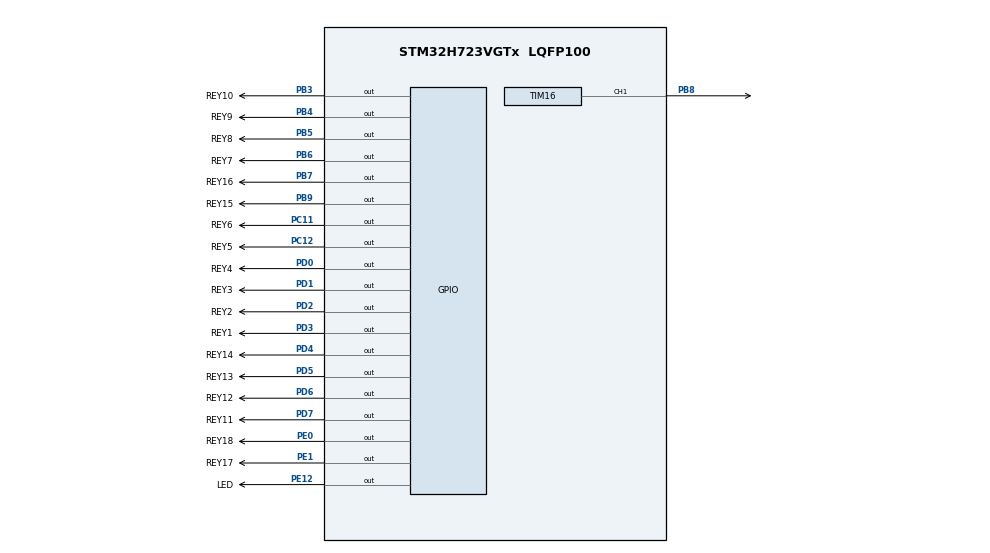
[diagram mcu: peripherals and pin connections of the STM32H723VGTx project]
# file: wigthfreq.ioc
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CORTEX_M7.default_mode_Activation=1
Mcu.Family=STM32H7
Mcu.Name=STM32H723VGTx
Mcu.Package=LQFP100
Mcu.UserConstants=PSC_VALUE,(1-1);ARR_VALUE,(12-1)
NVIC.PriorityGroup=NVIC_PRIORITYGROUP_4
NVIC.TIM6_DAC_IRQn=true\:15\:0\:false\:false\:true\:false\:true\:true
NVIC.TimeBase=TIM6_DAC_IRQn
NVIC.TimeBaseIP=TIM6
PB3(JTDO/TRACESWO).GPIO_Label=REY10
PB3(JTDO/TRACESWO).GPIO_ModeDefaultOutputPP=GPIO_MODE_OUTPUT_PP
PB3(JTDO/TRACESWO).GPIO_PuPd=GPIO_PULLUP
PB3(JTDO/TRACESWO).GPIO_Speed=GPIO_SPEED_FREQ_LOW
PB3(JTDO/TRACESWO).PinState=GPIO_PIN_SET
PB3(JTDO/TRACESWO).Signal=GPIO_Output
PB4(NJTRST).GPIO_Label=REY9
PB4(NJTRST).GPIO_ModeDefaultOutputPP=GPIO_MODE_OUTPUT_PP
PB4(NJTRST).GPIO_PuPd=GPIO_PULLUP
PB4(NJTRST).GPIO_Speed=GPIO_SPEED_FREQ_LOW
PB4(NJTRST).PinState=GPIO_PIN_SET
PB4(NJTRST).Signal=GPIO_Output
PB5.GPIO_Label=REY8
PB5.GPIO_ModeDefaultOutputPP=GPIO_MODE_OUTPUT_PP
PB5.GPIO_PuPd=GPIO_PULLUP
PB5.GPIO_Speed=GPIO_SPEED_FREQ_LOW
PB5.PinState=GPIO_PIN_SET
PB5.Signal=GPIO_Output
PB6.GPIO_Label=REY7
PB6.GPIO_ModeDefaultOutputPP=GPIO_MODE_OUTPUT_PP
PB6.GPIO_PuPd=GPIO_PULLUP
PB6.GPIO_Speed=GPIO_SPEED_FREQ_LOW
PB6.PinState=GPIO_PIN_SET
PB6.Signal=GPIO_Output
PB7.GPIO_Label=REY16
PB7.GPIO_ModeDefaultOutputPP=GPIO_MODE_OUTPUT_PP
PB7.GPIO_PuPd=GPIO_PULLUP
PB7.GPIO_Speed=GPIO_SPEED_FREQ_LOW
PB7.PinState=GPIO_PIN_SET
PB7.Signal=GPIO_Output
PB8.Signal=S_TIM16_CH1
PB9.GPIO_Label=REY15
PB9.GPIO_ModeDefaultOutputPP=GPIO_MODE_OUTPUT_PP
PB9.GPIO_PuPd=GPIO_PULLUP
PB9.GPIO_Speed=GPIO_SPEED_FREQ_LOW
PB9.PinState=GPIO_PIN_SET
PB9.Signal=GPIO_Output
PC11.GPIO_Label=REY6
PC11.GPIO_ModeDefaultOutputPP=GPIO_MODE_OUTPUT_PP
PC11.GPIO_PuPd=GPIO_PULLUP
PC11.GPIO_Speed=GPIO_SPEED_FREQ_LOW
PC11.PinState=GPIO_PIN_SET
PC11.Signal=GPIO_Output
PC12.GPIO_Label=REY5
PC12.GPIO_ModeDefaultOutputPP=GPIO_MODE_OUTPUT_PP
PC12.GPIO_PuPd=GPIO_PULLUP
PC12.GPIO_Speed=GPIO_SPEED_FREQ_LOW
PC12.PinState=GPIO_PIN_SET
PC12.Signal=GPIO_Output
PD0.GPIO_Label=REY4
PD0.GPIO_ModeDefaultOutputPP=GPIO_MODE_OUTPUT_PP
PD0.GPIO_PuPd=GPIO_PULLUP
PD0.GPIO_Speed=GPIO_SPEED_FREQ_LOW
PD0.PinState=GPIO_PIN_SET
PD0.Signal=GPIO_Output
PD1.GPIO_Label=REY3
PD1.GPIO_ModeDefaultOutputPP=GPIO_MODE_OUTPUT_PP
PD1.GPIO_PuPd=GPIO_PULLUP
PD1.GPIO_Speed=GPIO_SPEED_FREQ_LOW
PD1.PinState=GPIO_PIN_SET
PD1.Signal=GPIO_Output
PD2.GPIO_Label=REY2
PD2.GPIO_ModeDefaultOutputPP=GPIO_MODE_OUTPUT_PP
PD2.GPIO_PuPd=GPIO_PULLUP
PD2.GPIO_Speed=GPIO_SPEED_FREQ_LOW
PD2.PinState=GPIO_PIN_SET
PD2.Signal=GPIO_Output
PD3.GPIO_Label=REY1
PD3.GPIO_ModeDefaultOutputPP=GPIO_MODE_OUTPUT_PP
PD3.GPIO_PuPd=GPIO_PULLUP
PD3.GPIO_Speed=GPIO_SPEED_FREQ_LOW
PD3.PinState=GPIO_PIN_SET
PD3.Signal=GPIO_Output
PD4.GPIO_Label=REY14
PD4.GPIO_ModeDefaultOutputPP=GPIO_MODE_OUTPUT_PP
PD4.GPIO_PuPd=GPIO_PULLUP
PD4.GPIO_Speed=GPIO_SPEED_FREQ_LOW
PD4.PinState=GPIO_PIN_SET
PD4.Signal=GPIO_Output
PD5.GPIO_Label=REY13
PD5.GPIO_ModeDefaultOutputPP=GPIO_MODE_OUTPUT_PP
PD5.GPIO_PuPd=GPIO_PULLUP
PD5.GPIO_Speed=GPIO_SPEED_FREQ_LOW
PD5.PinState=GPIO_PIN_SET
PD5.Signal=GPIO_Output
PD6.GPIO_Label=REY12
PD6.GPIO_ModeDefaultOutputPP=GPIO_MODE_OUTPUT_PP
PD6.GPIO_PuPd=GPIO_PULLUP
PD6.GPIO_Speed=GPIO_SPEED_FREQ_LOW
PD6.PinState=GPIO_PIN_SET
PD6.Signal=GPIO_Output
PD7.GPIO_Label=REY11
PD7.GPIO_ModeDefaultOutputPP=GPIO_MODE_OUTPUT_PP
PD7.GPIO_PuPd=GPIO_PULLUP
PD7.GPIO_Speed=GPIO_SPEED_FREQ_LOW
PD7.PinState=GPIO_PIN_SET
PD7.Signal=GPIO_Output
PE0.GPIO_Label=REY18
PE0.GPIO_ModeDefaultOutputPP=GPIO_MODE_OUTPUT_PP
PE0.GPIO_PuPd=GPIO_PULLUP
PE0.GPIO_Speed=GPIO_SPEED_FREQ_LOW
PE0.PinState=GPIO_PIN_SET
PE0.Signal=GPIO_Output
PE1.GPIO_Label=REY17
PE1.GPIO_ModeDefaultOutputPP=GPIO_MODE_OUTPUT_PP
PE1.GPIO_PuPd=GPIO_PULLUP
PE1.GPIO_Speed=GPIO_SPEED_FREQ_LOW
PE1.PinState=GPIO_PIN_SET
PE1.Signal=GPIO_Output
PE12.GPIO_Label=LED
PE12.GPIO_ModeDefaultOutputPP=GPIO_MODE_OUTPUT_PP
PE12.GPIO_PuPd=GPIO_PULLUP
PE12.GPIO_Speed=GPIO_SPEED_FREQ_LOW
PE12.PinState=GPIO_PIN_SET
PE12.Signal=GPIO_Output
PH0-OSC_IN.Mode=HSE-External-Oscillator
PH0-OSC_IN.Signal=RCC_OSC_IN
PH1-OSC_OUT.Mode=HSE-External-Oscillator
PH1-OSC_OUT.Signal=RCC_OSC_OUT
ProjectManager.HeapSize=0x200
ProjectManager.StackSize=0x400
ProjectManager.TargetToolchain=CMake
RCC.ADCFreq_Value=129000000
RCC.APB1Freq_Value=120000000
RCC.APB2Freq_Value=120000000
RCC.APB3Freq_Value=120000000
RCC.APB4Freq_Value=120000000
RCC.CortexFreq_Value=480000000
RCC.D1PPRE=RCC_APB3_DIV2
RCC.D2PPRE1=RCC_APB1_DIV2
RCC.D2PPRE2=RCC_APB2_DIV2
RCC.D3PPRE=RCC_APB4_DIV2
RCC.DIVM1=4
RCC.DIVN1=30
RCC.DIVP1=1
RCC.HCLKFreq_Value=240000000
RCC.HPRE=RCC_HCLK_DIV2
RCC.HSE_VALUE=16000000
RCC.PLL2FRACN=0
RCC.PLL3FRACN=0
RCC.PLLFRACN=0
RCC.SYSCLKFreq_VALUE=480000000
RCC.SYSCLKSource=RCC_SYSCLKSOURCE_PLLCLK
RCC.USBFreq_Value=240000000
SH.S_TIM16_CH1.0=TIM16_CH1,PWM Generation1 CH1
TIM16.Channel=TIM_CHANNEL_1
VP_MEMORYMAP_VS_MEMORYMAP.Mode=CurAppReg
VP_SYS_VS_tim6.Mode=TIM6
VP_TIM16_VS_ClockSourceINT.Mode=Enable_Timer
VP_TIM16_VS_OPM.Mode=OPM_bit
board=custom

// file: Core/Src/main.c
/* USER CODE BEGIN Header */
/**
  ******************************************************************************
  * @file           : main.c
  * @brief          : Main program body
  ******************************************************************************
  * @attention
  *
  * Copyright (c) 2026 STMicroelectronics.
  * All rights reserved.
  *
  * This software is licensed under terms that can be found in the LICENSE file
  * in the root directory of this software component.
  * If no LICENSE file comes with this software, it is provided AS-IS.
  *
  ******************************************************************************
  */
/* USER CODE END Header */
#include "main.h"
#include "stm32h7xx_hal_gpio.h"
#include "tim.h"
#include "gpio.h"

/* USER CODE BEGIN Includes */
#include "self_task.h"
/* USER CODE END Includes */

void SystemClock_Config(void);
static void MPU_Config(void);

int main(void)
{

  /* MPU Configuration--------------------------------------------------------*/
  MPU_Config();

  /* MCU Configuration--------------------------------------------------------*/

  /* Reset of all peripherals, Initializes the Flash interface and the Systick. */
  HAL_Init();

  /* Configure the system clock */
  SystemClock_Config();

  /* Initialize all configured peripherals */
  MX_GPIO_Init();
  MX_TIM16_Init();
  /* USER CODE BEGIN 2 */
  self_task_start();
  /* USER CODE END 2 */

  /* Infinite loop */
  while (1)
  {

  }
}

void SystemClock_Config(void)
{
  RCC_OscInitTypeDef RCC_OscInitStruct = {0};
  RCC_ClkInitTypeDef RCC_ClkInitStruct = {0};

  /** Supply configuration update enable
  */
  HAL_PWREx_ConfigSupply(PWR_LDO_SUPPLY);

  /** Configure the main internal regulator output voltage
  */
  __HAL_PWR_VOLTAGESCALING_CONFIG(PWR_REGULATOR_VOLTAGE_SCALE0);

  while(!__HAL_PWR_GET_FLAG(PWR_FLAG_VOSRDY)) {}

  /** Initializes the RCC Oscillators according to the specified parameters
  * in the RCC_OscInitTypeDef structure.
  */
  RCC_OscInitStruct.OscillatorType = RCC_OSCILLATORTYPE_HSI;
  RCC_OscInitStruct.HSIState = RCC_HSI_DIV1;
  RCC_OscInitStruct.HSICalibrationValue = 64;
  RCC_OscInitStruct.PLL.PLLState = RCC_PLL_ON;
  RCC_OscInitStruct.PLL.PLLSource = RCC_PLLSOURCE_HSI;
  RCC_OscInitStruct.PLL.PLLM = 4;
  RCC_OscInitStruct.PLL.PLLN = 30;
  RCC_OscInitStruct.PLL.PLLP = 1;
  RCC_OscInitStruct.PLL.PLLQ = 2;
  RCC_OscInitStruct.PLL.PLLR = 2;
  RCC_OscInitStruct.PLL.PLLRGE = RCC_PLL1VCIRANGE_3;
  RCC_OscInitStruct.PLL.PLLVCOSEL = RCC_PLL1VCOWIDE;
  RCC_OscInitStruct.PLL.PLLFRACN = 0;
  if (HAL_RCC_OscConfig(&RCC_OscInitStruct) != HAL_OK)
  {
    Error_Handler();
  }

  /** Initializes the CPU, AHB and APB buses clocks
  */
  RCC_ClkInitStruct.ClockType = RCC_CLOCKTYPE_HCLK|RCC_CLOCKTYPE_SYSCLK
                              |RCC_CLOCKTYPE_PCLK1|RCC_CLOCKTYPE_PCLK2
                              |RCC_CLOCKTYPE_D3PCLK1|RCC_CLOCKTYPE_D1PCLK1;
  RCC_ClkInitStruct.SYSCLKSource = RCC_SYSCLKSOURCE_PLLCLK;
  RCC_ClkInitStruct.SYSCLKDivider = RCC_SYSCLK_DIV1;
  RCC_ClkInitStruct.AHBCLKDivider = RCC_HCLK_DIV2;
  RCC_ClkInitStruct.APB3CLKDivider = RCC_APB3_DIV2;
  RCC_ClkInitStruct.APB1CLKDivider = RCC_APB1_DIV2;
  RCC_ClkInitStruct.APB2CLKDivider = RCC_APB2_DIV2;
  RCC_ClkInitStruct.APB4CLKDivider = RCC_APB4_DIV2;

  if (HAL_RCC_ClockConfig(&RCC_ClkInitStruct, FLASH_LATENCY_3) != HAL_OK)
  {
    Error_Handler();
  }
}

 /* MPU Configuration */

void MPU_Config(void)
{
  MPU_Region_InitTypeDef MPU_InitStruct = {0};

  /* Disables the MPU */
  HAL_MPU_Disable();

  /** Initializes and configures the Region and the memory to be protected
  */
  MPU_InitStruct.Enable = MPU_REGION_ENABLE;
  MPU_InitStruct.Number = MPU_REGION_NUMBER0;
  MPU_InitStruct.BaseAddress = 0x0;
  MPU_InitStruct.Size = MPU_REGION_SIZE_4GB;
  MPU_InitStruct.SubRegionDisable = 0x87;
  MPU_InitStruct.TypeExtField = MPU_TEX_LEVEL0;
  MPU_InitStruct.AccessPermission = MPU_REGION_NO_ACCESS;
  MPU_InitStruct.DisableExec = MPU_INSTRUCTION_ACCESS_DISABLE;
  MPU_InitStruct.IsShareable = MPU_ACCESS_SHAREABLE;
  MPU_InitStruct.IsCacheable = MPU_ACCESS_NOT_CACHEABLE;
  MPU_InitStruct.IsBufferable = MPU_ACCESS_NOT_BUFFERABLE;

  HAL_MPU_ConfigRegion(&MPU_InitStruct);
  /* Enables the MPU */
  HAL_MPU_Enable(MPU_PRIVILEGED_DEFAULT);

}

void HAL_TIM_PeriodElapsedCallback(TIM_HandleTypeDef *htim)
{
  if (htim->Instance == TIM6)
  {
    HAL_IncTick();
  }
}

void Error_Handler(void)
{
  __disable_irq();
  while (1)
  {
  }
}
